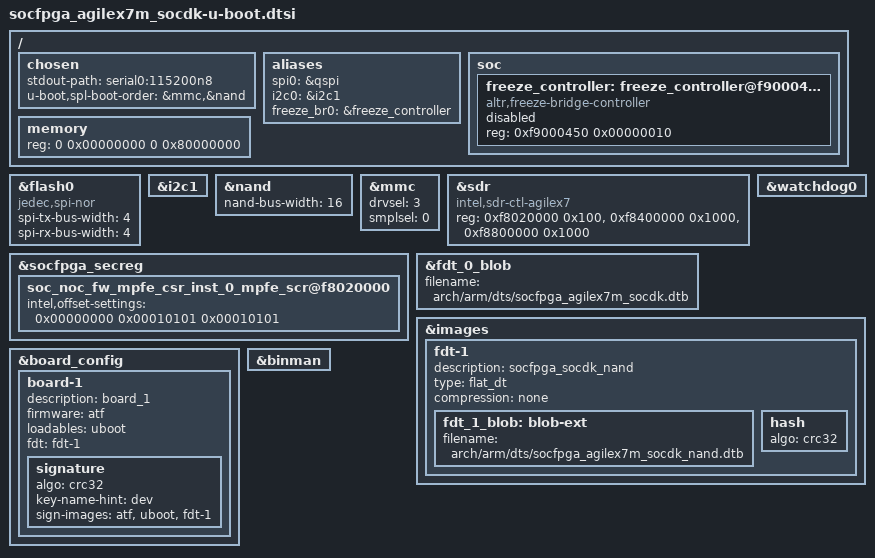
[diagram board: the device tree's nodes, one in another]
// SPDX-License-Identifier: GPL-2.0+
/*
 * U-Boot additions
 *
 * Copyright (C) 2023 Intel Corporation <www.intel.com>
 */

#include "socfpga_agilex-u-boot.dtsi"

/{
	chosen {
		stdout-path = "serial0:115200n8";
		u-boot,spl-boot-order = &mmc,&nand;
	};

	aliases {
		spi0 = &qspi;
		i2c0 = &i2c1;
		freeze_br0 = &freeze_controller;
	};

	soc {
		freeze_controller: freeze_controller@f9000450 {
			compatible = "altr,freeze-bridge-controller";
			reg = <0xf9000450 0x00000010>;
			status = "disabled";
		};
	};

	memory {
		/*  if run HBM on FIB device, set to 1GB
		 *  reg = <0 0x00000000 0 0x40000000>;
		 */

		/* 2GB */
		reg = <0 0x00000000 0 0x80000000>;
	};
};

&flash0 {
	compatible = "jedec,spi-nor";
	spi-tx-bus-width = <4>;
	spi-rx-bus-width = <4>;
	bootph-all;
	/delete-property/ cdns,read-delay;
};

&i2c1 {
	status = "okay";
};

&nand {
	status = "okay";
	nand-bus-width = <16>;
	bootph-all;
};

&mmc {
	drvsel = <3>;
	smplsel = <0>;
	bootph-all;
};

&sdr {
	compatible = "intel,sdr-ctl-agilex7";
	/delete-property/ reg;
	/*  if use HBM
	 *  reg = <0xf8020000 0x100>,
	 *        <0xf8400000 0x1000>,
	 *        <0xf8410000 0x1000>;
	 */

	reg = <0xf8020000 0x100>,
	      <0xf8400000 0x1000>,
	      <0xf8800000 0x1000>;
};

&socfpga_secreg {
	soc_noc_fw_mpfe_csr_inst_0_mpfe_scr@f8020000 {
	/delete-property/ intel,offset-settings;
	intel,offset-settings =
		/* Disable MPFE firewall for SMMU */
		<0x00000000 0x00010101 0x00010101>;
	};
};

&watchdog0 {
	bootph-all;
};

#if !defined(CONFIG_SOCFPGA_SECURE_VAB_AUTH)
&fdt_0_blob {
	filename = "arch/arm/dts/socfpga_agilex7m_socdk.dtb";
};

&images {
	fdt-1 {
		description = "socfpga_socdk_nand";
		type = "flat_dt";
		compression = "none";
		fdt_1_blob: blob-ext {
			filename = "arch/arm/dts/socfpga_agilex7m_socdk_nand.dtb";
		};
		hash {
			algo = "crc32";
		};
	};
};

&board_config {
	board-1 {
		description = "board_1";
		firmware = "atf";
		loadables = "uboot";
		fdt = "fdt-1";
		signature {
			algo = "crc32";
			key-name-hint = "dev";
			sign-images = "atf", "uboot", "fdt-1";
		};
	};
};

&binman {
	/delete-node/ kernel;
};
#endif

